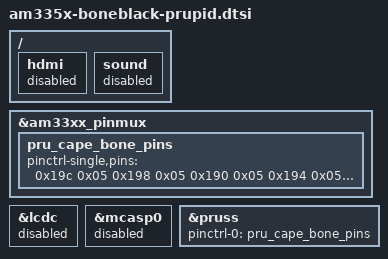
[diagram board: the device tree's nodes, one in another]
/*
 * Copyright (C) 2016 Texas Instruments Incorporated - http://www.ti.com/
 *
 * This program is free software; you can redistribute it and/or modify
 * it under the terms of the GNU General Public License version 2 as
 * published by the Free Software Foundation.
 */

&am33xx_pinmux {
	pru_cape_bone_pins: pru_cape_bone_pins {
		pinctrl-single,pins = <
			0x19c 0x05	/* mcasp0_ahclkr, OMAP_MUX_MODE5 | AM33XX_PIN_OUTPUT, PRU CAPE Red LED */
			0x198 0x05	/* mcasp0_axr0, OMAP_MUX_MODE5 | AM33XX_PIN_OUTPUT, PRU CAPE Orange LED */
			0x190 0x05	/* mcasp0_aclkx, OMAP_MUX_MODE5 | AM33XX_PIN_OUTPUT, PRU CAPE Blue LED */
			0x194 0x05	/* mcasp0_fsx, OMAP_MUX_MODE5 | AM33XX_PIN_OUTPUT, PRU CAPE Green LED */
			0x0ac 0x05	/* lcd_data3, OMAP_MUX_MODE5 | AM33XX_PIN_OUTPUT, PRU CAPE RGB_0 LED, HDMI Conf. */
			0x0b0 0x05	/* lcd_data4, OMAP_MUX_MODE5 | AM33XX_PIN_OUTPUT, PRU CAPE RGB_1 LED, HDMI Conf. */
			0x0b4 0x05	/* lcd_data5, OMAP_MUX_MODE5 | AM33XX_PIN_OUTPUT, PRU CAPE RGB_2 LED, HDMI Conf. */
		
			0x164 (PIN_OUTPUT_PULLDOWN | MUX_MODE3) /* ECAP PWM      P9->42 */
 
			0x0D0 (PIN_INPUT_PULLDOWN | MUX_MODE2)  /* eQEP1A_in     P8->35 */
			0x0D4 (PIN_INPUT_PULLDOWN | MUX_MODE2)  /* eQEP1B_in     P8->33 */
		>;
	};
};

&lcdc {
	status = "disabled";  		/* Disable HDMI due to pin mux conflicts with PRU Cape */
};

/{
	hdmi {
		status = "disabled";
	};
};

&mcasp0 {
	status = "disabled";
};

/{
	sound {
		status = "disabled";
	};
};

&pruss {
        pinctrl-names = "default";
	pinctrl-0 = <&pru_cape_bone_pins>;
};
